# S32K312_M7 register map
Vendor: NXP Semiconductors; File version: 1.4
CPU: CM7 r0p1, little endian, MPU, FPU, VTOR, 4 interrupt priority bits
Registers are 32-bit, read-write, reset 0x0 unless marked. A register's access mark holds for its fields unless they carry their own. Offsets are from the block's base; [hi:lo] are bit positions; lines under a group give offsets from that group; {n}, {i} and the like mark numbered series; 'fields as' and 'values as' point back to an identical list.

## TRGMUX
Base 0x40080000
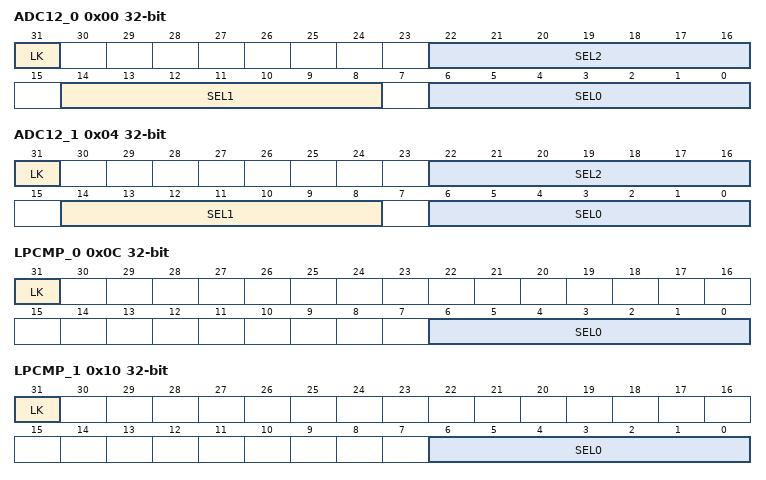
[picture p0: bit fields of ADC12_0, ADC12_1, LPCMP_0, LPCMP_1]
0x00 ADC12_0 — TRGMUX ADC12_0 Register
  [31] LK — TRGMUX register lock.
    0=UNLOCKED (Register can be written.); 1=LOCKED (Register cannot be written until the next system Reset.)
  [22:16] SEL2 — Trigger MUX Input 2 Source Select
  [14:8] SEL1 — Trigger MUX Input 1 Source Select
  [6:0] SEL0 — Trigger MUX Input 0 Source Select
0x04 ADC12_1 — TRGMUX ADC12_1 Register
  fields as ADC12_0
0x0C LPCMP_0 — TRGMUX LPCMP_0 Register
  [31] LK — TRGMUX register lock.
    values as ADC12_0.LK
  [6:0] SEL0 — Trigger MUX Input 0 Source Select
0x10 LPCMP_1 — TRGMUX LPCMP_1 Register
  fields as LPCMP_0
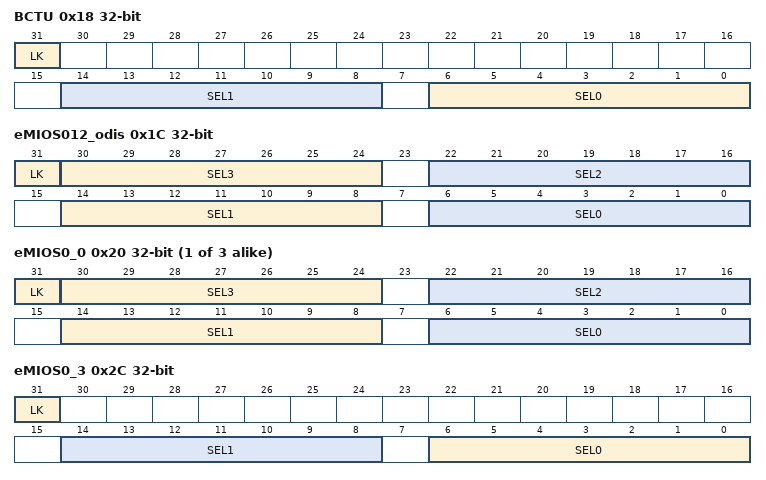
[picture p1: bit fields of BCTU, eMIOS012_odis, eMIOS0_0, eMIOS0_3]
0x18 BCTU — TRGMUX BCTU Register
  [31] LK — TRGMUX register lock.
    values as ADC12_0.LK
  [14:8] SEL1 — Trigger MUX Input 1 Source Select
  [6:0] SEL0 — Trigger MUX Input 0 Source Select
0x1C eMIOS012_odis — TRGMUX eMIOS012_odis Register
  [31] LK — TRGMUX register lock.
    values as ADC12_0.LK
  [8n+6:8n] SEL{n} (n=0..3) — Trigger MUX Input {n} Source Select
{0x20+4i} eMIOS0_{i} (i=0..2) — TRGMUX eMIOS0_{i} Register
  fields as eMIOS012_odis
0x2C eMIOS0_3 — TRGMUX eMIOS0_3 Register
  fields as BCTU
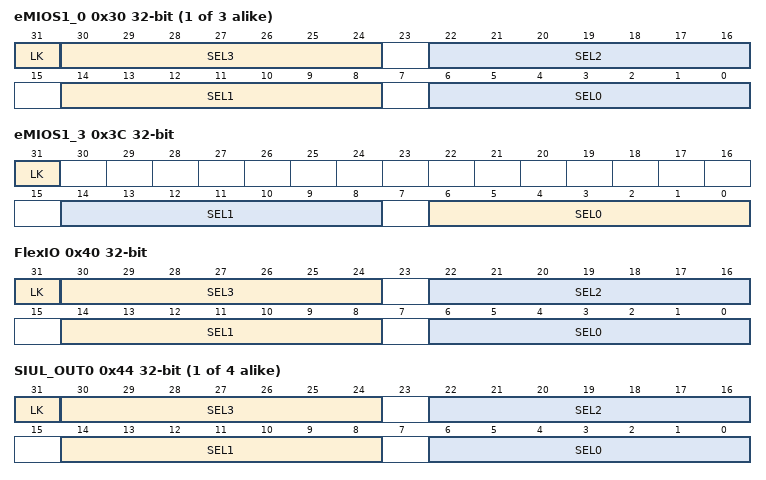
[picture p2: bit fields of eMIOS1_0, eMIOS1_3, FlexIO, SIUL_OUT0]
{0x30+4i} eMIOS1_{i} (i=0..2) — TRGMUX eMIOS1_{i} Register
  fields as eMIOS012_odis
0x3C eMIOS1_3 — TRGMUX eMIOS1_3 Register
  fields as BCTU
0x40 FlexIO — TRGMUX FlexIO Register
  fields as eMIOS012_odis
{0x44+4i} SIUL_OUT{i} (i=0..3) — TRGMUX SIUL_OUT{i} Register
  fields as eMIOS012_odis
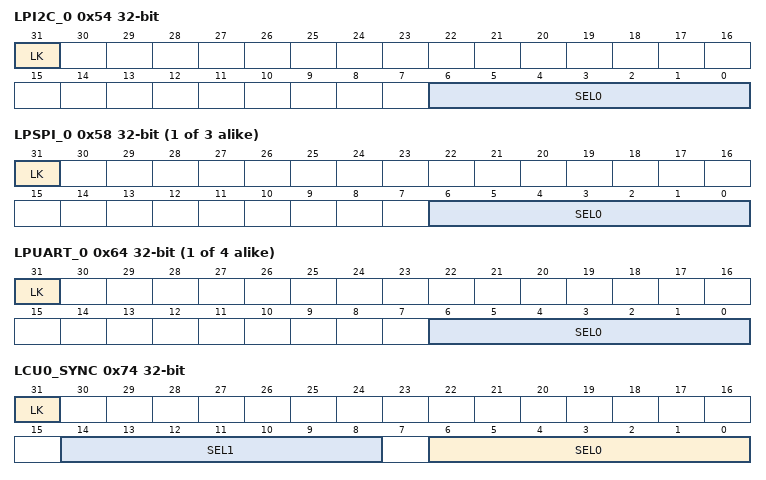
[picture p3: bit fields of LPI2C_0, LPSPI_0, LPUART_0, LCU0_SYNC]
0x54 LPI2C_0 — TRGMUX LPI2C_0 Register
  fields as LPCMP_0
{0x58+4i} LPSPI_{i} (i=0..2) — TRGMUX LPSPI_{i} Register
  fields as LPCMP_0
{0x64+4i} LPUART_{i} (i=0..3) — TRGMUX LPUART_{i} Register
  fields as LPCMP_0
0x74 LCU0_SYNC — TRGMUX LCU0_SYNC Register
  fields as BCTU
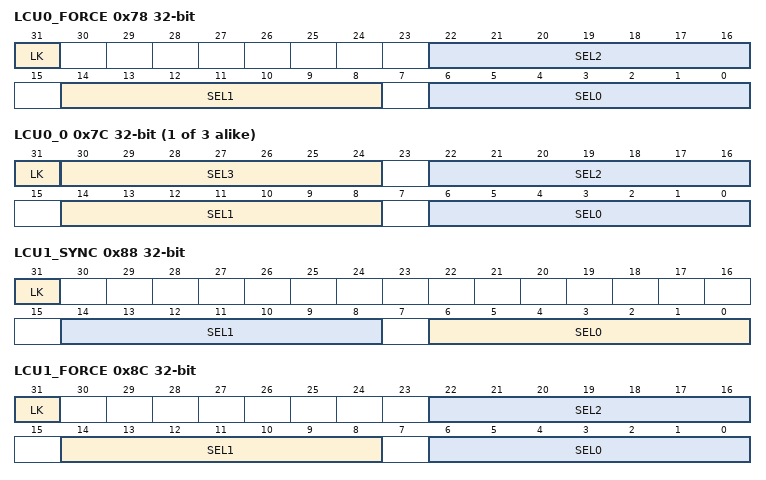
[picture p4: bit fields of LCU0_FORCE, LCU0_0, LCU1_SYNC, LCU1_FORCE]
0x78 LCU0_FORCE — TRGMUX LCU0_FORCE Register
  fields as ADC12_0
{0x7C+4i} LCU0_{i} (i=0..2) — TRGMUX LCU0_{i} Register
  fields as eMIOS012_odis
0x88 LCU1_SYNC — TRGMUX LCU1_SYNC Register
  fields as BCTU
0x8C LCU1_FORCE — TRGMUX LCU1_FORCE Register
  fields as ADC12_0
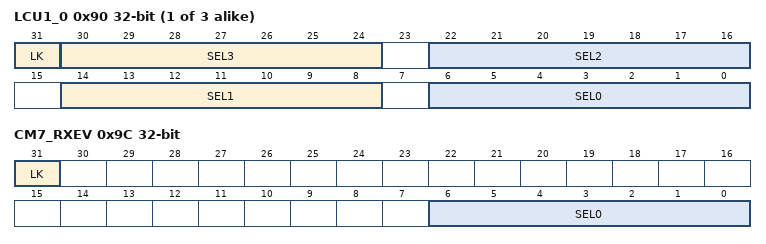
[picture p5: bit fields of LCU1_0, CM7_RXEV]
{0x90+4i} LCU1_{i} (i=0..2) — TRGMUX LCU1_{i} Register
  fields as eMIOS012_odis
0x9C CM7_RXEV — TRGMUX CM7_RXEV Register
  fields as LPCMP_0

## LCU_0 — LCU
Base 0x40098000
Same registers: LCU_1 0x4009C000
{0x0+0x40*i} LC[{i}] (i=0..2) group — Logic Control array
  {0x0+4j} LC_LUTCTRL{j} (j=0..3) — LC n Output m LUT Control
    [15:0] LUTCTRL — LUT Control
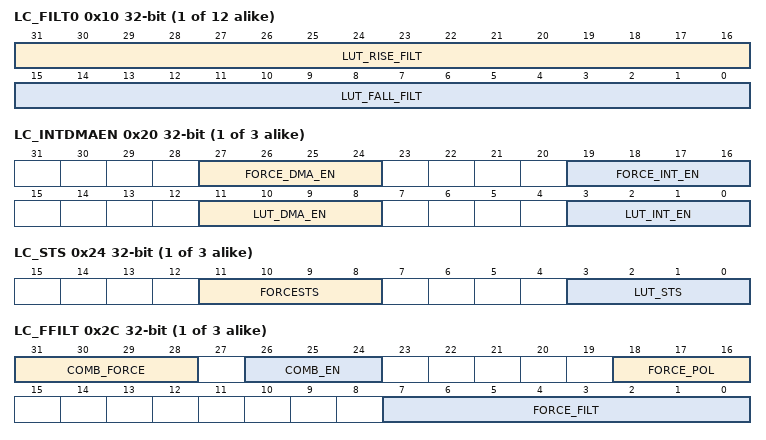
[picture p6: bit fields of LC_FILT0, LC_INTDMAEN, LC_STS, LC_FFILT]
  {0x10+4j} LC_FILT{j} (j=0..3) — LC n Output m Filter
    [31:16] LUT_RISE_FILT — Rise Filter
      0=Bypass filter
    [15:0] LUT_FALL_FILT — Fall Filter
      0=Bypass filter
  0x20 LC_INTDMAEN — LC n Interrupt and DMA Enable
    [27:24] FORCE_DMA_EN — Force DMA Enable
    [19:16] FORCE_INT_EN — Force Interrupt Enable
    [11:8] LUT_DMA_EN — LUT DMA Enable
    [3:0] LUT_INT_EN — LUT Interrupt Enable
  0x24 LC_STS write-1-clears — LC n Status
    [11:8] FORCESTS write-1-clears — Force Event
    [3:0] LUT_STS write-1-clears — LUT Event
  0x28 LC_OUTPOL — LC n Output Polarity Control
    [3:0] OUTPOL — Output Polarity
  0x2C LC_FFILT — LC n Force Filter
    [31:28] COMB_FORCE ro — Combined Sensed Force Input
    [26:24] COMB_EN — Combinational Force Path (CFP) Enable
    [18:16] FORCE_POL — Force Input Polarity
    [7:0] FORCE_FILT — Force Filter
      0=Bypass filter
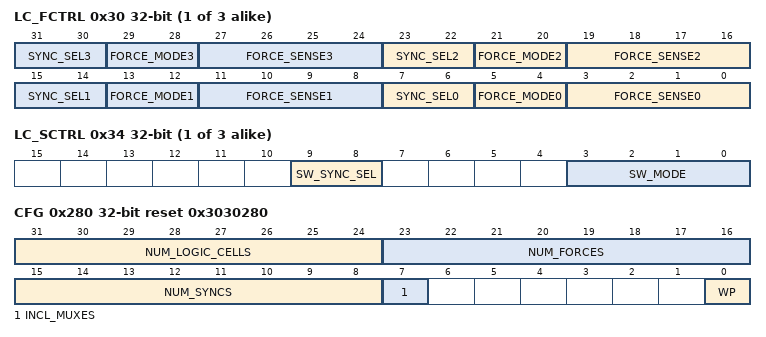
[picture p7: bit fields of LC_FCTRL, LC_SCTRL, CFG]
  0x30 LC_FCTRL — LC n Force Control
    [8n+7:8n+6] SYNC_SEL{n} (n=0..3) — Sync Select
      0=input0 (Sync input 0); 1=input1 (Sync input 1)
    [8n+5:8n+4] FORCE_MODE{n} (n=0..3) — Force Clearing Mode
      0=force_deassertion{n} (Deassertion); 1=rising_sync_after_force_deassertion{n} (Rising sync after deassertion); 2=w1c_after_force_deassertion{n} (Writing 1 after deassertion); 3=rising_sync_after_w1c_and_force_deassertion{n} (Rising sync after writing 1 and deassertion)
    [8n+3:8n] FORCE_SENSE{n} (n=0..3) — Force Input Sensitivity
  0x34 LC_SCTRL — LC n Sync Control
    [9:8] SW_SYNC_SEL — Software Sync Select
      0=input0 (Sync input 0); 1=input1 (Sync input 1)
    [3:0] SW_MODE — Software Sync Mode
{0x200+4i} MUXSEL[{i}] (i=0..11) — Mux Select
  [7:0] MUXSEL
    0=logic_0; {v}=lu_in_{v} (LU_IN0 to LU_IN11) (v=1..9); {v}=lu_out_{v} (LU_OUT0 to LU_OUT11) (v=13..24)
0x280 CFG reset 0x3030280 — Configuration
  [31:24] NUM_LOGIC_CELLS ro — LCs
  [23:16] NUM_FORCES ro — Force Inputs
  [15:8] NUM_SYNCS ro — Sync Inputs
  [7] INCL_MUXES ro — Input Muxing
    0=no (Not supported); 1=yes (Supported)
  [0] WP — Write Protect
0x284 SWEN — Software Override Enable
  [11:0] SWEN
0x288 SWVALUE — Software Override Value
  [11:0] SWVALUE
0x28C OUTEN — Output Enable
  [11:0] OUTEN — Output Enables
0x290 LCIN ro — Logic Inputs
  [11:0] LC_INPUTS
0x294 SWOUT ro — Overridden Inputs
  [11:0] SWOUT
0x298 LCOUT ro — Logic Outputs
  [11:0] LCOUT
0x29C FORCEOUT ro — Forced Outputs
  [11:0] FORCEOUT
0x2A0 FORCESTS write-1-clears — Force Status
  [11:0] FORCESTS write-1-clears
0x2A8 DBGEN — Debug Mode Enable
  [11:0] DBGEN

## Notices in the file
Copyright 2016-2022 NXP
NXP Confidential. This software is owned or controlled by NXP and may only be
used strictly in accordance with the applicable license terms. By expressly
accepting such terms or by downloading, installing, activating and/or otherwise
using the software, you are agreeing that you have read, and that you agree to
comply with and are bound by, such license terms. If you do not agree to be
bound by the applicable license terms, then you may not retain, install,
activate or otherwise use the software. The production use license in
Section 2.3 is expressly granted for this software.
